# PKA_INT register map
Vendor: Texas Instruments
Peripheral module from a debugger description file (folder CC2652).
Registers are 32-bit, read-write, reset 0xFFFFFFFF unless marked. A register's access mark holds for its fields unless they carry their own. Offsets are as the file gives them; lines under a group give offsets from that group; [hi:lo] are bit positions; {n}, {i} and the like mark numbered series; 'fields as' and 'values as' point back to an identical list; <NAME> marks a mode.

## PKA_INT — Integrated module which includes the PKA K
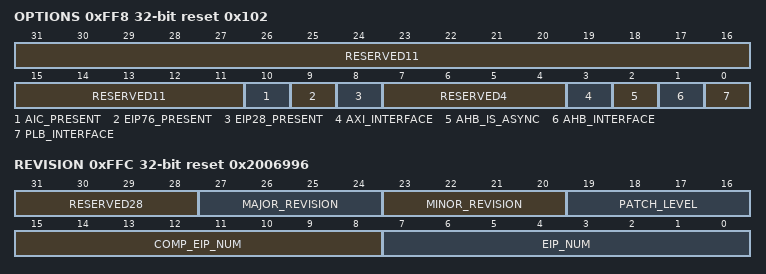
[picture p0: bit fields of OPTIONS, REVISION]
0xFF8 OPTIONS access not given reset 0x102 — PKA Options register
  [31:11] RESERVED11 ro — Ignore on read
  [10] AIC_PRESENT ro — When set to '1', indicates that an EIP201 AIC is included in the EIP150
  [9] EIP76_PRESENT ro — When set to '1', indicates that the EIP76 TRNG is included in the EIP150
  [8] EIP28_PRESENT ro — When set to '1', indicates that the EIP28 PKA is included in the EIP150
  [7:4] RESERVED4 ro — Ignore on read
  [3] AXI_INTERFACE ro — When set to '1', indicates that the EIP150 is equipped with a AXI interface
  [2] AHB_IS_ASYNC ro — When set to '1', indicates that AHB interface is asynchronous Only applicable when AHB_INTERFACE is 1
  [1] AHB_INTERFACE — When set to '1', indicates that the EIP150 is equipped with a AHB interface
  [0] PLB_INTERFACE — When set to '1', indicates that the EIP150 is equipped with a PLB interface
0xFFC REVISION ro reset 0x2006996 — PKA hardware revision register This register allows the host access to the hardware revision number of the PKA engine for software driver matching and diagnostic purposes. It is always located at the highest address in the access space of the module and contains an encoding of the EIP number (with its complement as signature) for recognition of the hardware module.
  [31:28] RESERVED28 — These bits should be ignored on read
  [27:24] MAJOR_REVISION — These bits encode the major version number for this module
  [23:20] MINOR_REVISION — These bits encode the minor version number for this module
  [19:16] PATCH_LEVEL — These bits encode the hardware patch level for this module they start at value 0 on the first release
  [15:8] COMP_EIP_NUM — These bits simply contain the complement of bits [7:0], used by a driver to ascertain that the EIP150 revision register is indeed read
  [7:0] EIP_NUM — These bits encode the AuthenTec EIP number for the EIP150
